# R7FA6M4AF register map
Vendor: Renesas Electronics Corporation; Series: RA6; File version: 1.30.00
CPU: CM33 r0p4, little endian, MPU, FPU, VTOR, 4 interrupt priority bits, 96 interrupts
Registers are 8-bit, read-write, reset 0x0 unless marked. A register's access mark holds for its fields unless they carry their own. Offsets are from the block's base; [hi:lo] are bit positions.

## EDMAC0 — DMA Controller for the Ethernet Controller Channel 0
Base 0x40114000
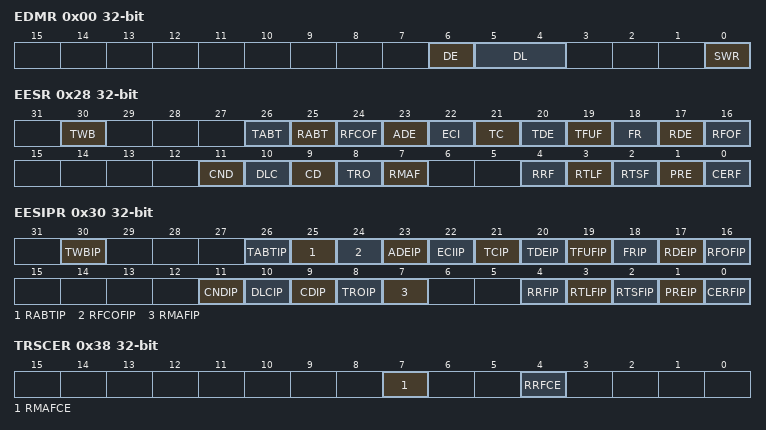
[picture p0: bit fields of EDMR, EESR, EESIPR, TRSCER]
0x00 EDMR 32-bit — EDMAC Mode Register
  [6] DE — Big Endian Mode/Little Endian Mode
  [5:4] DL — Transmit/Receive Descriptor Length
  [0] SWR — Software Reset
0x08 EDTRR 32-bit — EDMAC Transmit Request Register
  [0] TR — Transmit Request
0x10 EDRRR 32-bit — EDMAC Receive Request Register
  [0] RR — Receive Request
0x18 TDLAR 32-bit — Transmit Descriptor List Start Address Register
0x20 RDLAR 32-bit — Receive Descriptor List Start Address Register
0x28 EESR 32-bit — ETHERC/EDMAC Status Register
  [30] TWB — Write,Back Complete Flag
  [26] TABT — Transmit Abort Detect Flag
  [25] RABT — Receive Abort Detect Flag
  [24] RFCOF — Receive Frame Counter Overflow Flag
  [23] ADE — Address Error Flag
  [22] ECI ro — ETHERC Status Register Source Flag
  [21] TC — Frame Transfer Complete Flag
  [20] TDE — Transmit Descriptor Empty Flag
  [19] TFUF — Transmit FIFO Underflow Flag
  [18] FR — Frame Receive Flag
  [17] RDE — Receive Descriptor Empty Flag
  [16] RFOF — Receive FIFO Overflow Flag
  [11] CND — Carrier Not Detect Flag
  [10] DLC — Loss of Carrier Detect Flag
  [9] CD — Late Collision Detect Flag
  [8] TRO — Transmit Retry Over Flag
  [7] RMAF — Multicast Address Frame Receive Flag
  [4] RRF — Alignment Error Flag
  [3] RTLF — Frame,Too,Long Error Flag
  [2] RTSF — Frame,Too,Short Error Flag
  [1] PRE — PHY,LSI Receive Error Flag
  [0] CERF — CRC Error Flag
0x30 EESIPR 32-bit — ETHERC/EDMAC Status Interrupt Enable Register
  [30] TWBIP — Write,Back Complete Interrupt Request Enable
  [26] TABTIP — Transmit Abort Detect Interrupt Request Enable
  [25] RABTIP — Receive Abort Detect Interrupt Request Enable
  [24] RFCOFIP — Receive Frame Counter Overflow Interrupt Request Enable
  [23] ADEIP — Address Error Interrupt Request Enable
  [22] ECIIP — ETHERC Status Register Source Interrupt Request Enable
  [21] TCIP — Frame Transfer Complete Interrupt Request Enable
  [20] TDEIP — Transmit Descriptor Empty Interrupt Request Enable
  [19] TFUFIP — Transmit FIFO Underflow Interrupt Request Enable
  [18] FRIP — Frame Receive Interrupt Request Enable
  [17] RDEIP — Receive Descriptor Empty Interrupt Request Enable
  [16] RFOFIP — Receive FIFO Overflow Interrupt Request Enable
  [11] CNDIP — Carrier Not Detect Interrupt Request Enable
  [10] DLCIP — Loss of Carrier Detect Interrupt Request Enable
  [9] CDIP — Late Collision Detect Interrupt Request Enable
  [8] TROIP — Transmit Retry Over Interrupt Request Enable
  [7] RMAFIP — Multicast Address Frame Receive Interrupt Request Enable
  [4] RRFIP — Alignment Error Interrupt Request Enable
  [3] RTLFIP — Frame,Too,Long Error Interrupt Request Enable
  [2] RTSFIP — Frame,Too,Short Error Interrupt Request Enable
  [1] PREIP — PHY,LSI Receive Error Interrupt Request Enable
  [0] CERFIP — CRC Error Interrupt Request Enable
0x38 TRSCER 32-bit — ETHERC/EDMAC Transmit/Receive Status Copy Enable Register
  [7] RMAFCE — RMAF Flag Copy Enable
  [4] RRFCE — RRF Flag Copy Enable
0x40 RMFCR 32-bit — Missed,Frame Counter Register
  [15:0] MFC — Missed,Frame Counter
0x48 TFTR 32-bit — Transmit FIFO Threshold Register
  [10:0] TFT — Transmit FIFO Threshold
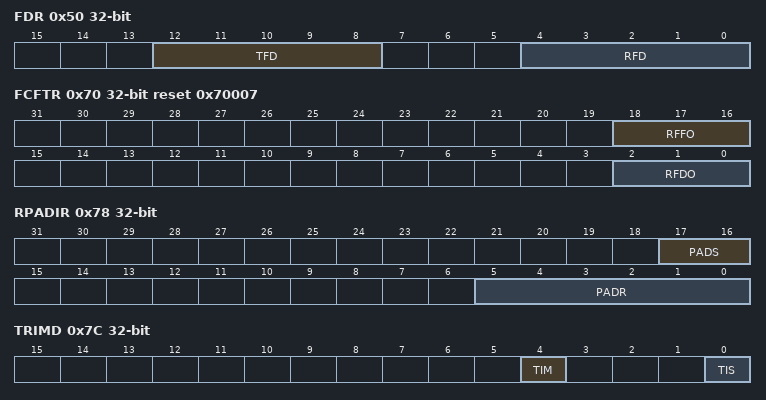
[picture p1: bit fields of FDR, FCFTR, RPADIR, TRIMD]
0x50 FDR 32-bit — FIFO Depth Register
  [12:8] TFD — Transmit FIFO Depth
  [4:0] RFD — Receive FIFO Depth
0x58 RMCR 32-bit — Receive Method Control Register
  [0] RNR — Receive Request Reset
0x64 TFUCR 32-bit — Transmit FIFO Underflow Counter
  [15:0] UNDER — Transmit FIFO Underflow Count
0x68 RFOCR 32-bit — Receive FIFO Overflow Counter
  [15:0] OVER — Receive FIFO Overflow Count
0x6C IOSR 32-bit — Independent Output Signal Setting Register
  [0] ELB — External Loopback Mode
0x70 FCFTR 32-bit reset 0x70007 — Flow Control Start FIFO Threshold Setting Register
  [18:16] RFFO — Receive FIFO Frame PAUSE Output Threshold
  [2:0] RFDO — Receive FIFO Data PAUSE Output Threshold
0x78 RPADIR 32-bit — Receive Data Padding Insert Register
  [17:16] PADS — Padding Size
  [5:0] PADR — Padding Slot
0x7C TRIMD 32-bit — Transmit Interrupt Setting Register
  [4] TIM — Transmit Interrupt Mode
  [0] TIS — Transmit Interrupt Enable
0xC8 RBWAR 32-bit ro — Receive Buffer Write Address Register
0xCC RDFAR 32-bit ro — Receive Descriptor Fetch Address Register
0xD4 TBRAR 32-bit ro — Transmit Buffer Read Address Register
0xD8 TDFAR 32-bit ro — Transmit Descriptor Fetch Address Register
